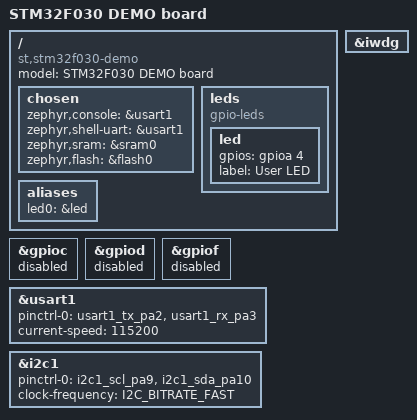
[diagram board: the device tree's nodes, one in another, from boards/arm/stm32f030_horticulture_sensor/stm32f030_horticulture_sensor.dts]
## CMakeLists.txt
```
set(BOARD_ROOT ${CMAKE_CURRENT_LIST_DIR})
set(BOARD stm32f030_horticulture_sensor)
# ===== DO NOT REMOVE =====
cmake_minimum_required(VERSION 3.13.1)
include($ENV{ZEPHYR_BASE}/cmake/app/boilerplate.cmake NO_POLICY_SCOPE)
# ===== DO NOT REMOVE =====

project(stm32-gauge)

target_sources(app PRIVATE src/main.c)


# This sample is only compatible with nrf52840_pca10065 because it has
# re-directed the 'boards' directory to a directory that only contains
# this board.
```

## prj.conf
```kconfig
# nothing here
CONFIG_GPIO=y
CONFIG_I2C_SLAVE=y
```

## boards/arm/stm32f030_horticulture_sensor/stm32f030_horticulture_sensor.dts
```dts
/*
 * Copyright (c) 2019 Antony Pavlov <antonynpavlov@gmail.com>
 *
 * SPDX-License-Identifier: Apache-2.0
 */

/dts-v1/;
#include <st/f0/stm32f030X4.dtsi>
#include <st/f0/stm32f030f4px-pinctrl.dtsi>

/ {
	model = "STM32F030 DEMO board";
	compatible = "st,stm32f030-demo";

	chosen {
		zephyr,console = &usart1;
		zephyr,shell-uart = &usart1;
		zephyr,sram = &sram0;
		zephyr,flash = &flash0;
	};

	leds {
		compatible = "gpio-leds";
		led: led {
			gpios = <&gpioa 4 GPIO_ACTIVE_HIGH>;
			label = "User LED";
		};
	};

	aliases {
		led0 = &led;
	};
};

/* Due to limited available memory, don't enable gpioc,d,e,f */
&gpioc {status = "disabled";};
&gpiod {status = "disabled";};
&gpiof {status = "disabled";};

&usart1 {
	pinctrl-0 = <&usart1_tx_pa2 &usart1_rx_pa3>;
	current-speed = <115200>;
	status = "okay";
};
&i2c1 {
	pinctrl-0 = < &i2c1_scl_pa9 &i2c1_sda_pa10 >;
	status = "okay";
	clock-frequency = <I2C_BITRATE_FAST>;
};


&iwdg {
	status = "okay";
};
```

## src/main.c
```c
/*
 * Copyright (c) 2016 Intel Corporation
 *
 * SPDX-License-Identifier: Apache-2.0
 */

#include <zephyr.h>
#include <device.h>
#include <devicetree.h>
#include <drivers/gpio.h>
#include <drivers/i2c.h>

/* 1000 msec = 1 sec */


/* The devicetree node identifier for the "led0" alias. */

/*
struct i2c_slave_callbacks {
	# callback function being called when write is requested 
	i2c_slave_write_requested_cb_t write_requested;
	# callback function being called when read is requested 
	i2c_slave_read_requested_cb_t read_requested;
	# callback function being called when byte has been received 
	i2c_slave_write_received_cb_t write_received;
	# callback function being called when byte has been sent 
	i2c_slave_read_processed_cb_t read_processed;
	# callback function being called when stop occurs on the bus 
	i2c_slave_stop_cb_t stop;
};
*/
void	i2c_write_requested(){
	printk("I2C: Write requested\n");
}
void	i2c_read_requested(){
	printk("I2C: Read requested\n");
}
void	i2c_write_received(){
	printk("I2C: write_received\n");
}
void	i2c_read_processed(){
	printk("I2C: read_processed\n");
}
void	i2c_read_processed(){
	printk("I2C: stop\n");
}
/*
struct i2c_slave_config {
	# Private, do not modify 
	sys_snode_t node;
	# Flags for the slave device defined by I2C_SLAVE_FLAGS_* constants 
	uint8_t flags;
	# Address for this slave device 
	uint16_t address;
	# Callback functions 
	const struct i2c_slave_callbacks *callbacks;
};
*/

i2c_slave_config i2c_config;


#define I2C_DEV "I2C_0"


void main(void)
{
const struct device *i2c_dev;
	i2c_dev = device_get_binding(I2C_DEV);
	if (!i2c_dev) {
		printk("I2C: Device driver not found.\n");
		return;
	}
	i2c_slave_register(i2c_dev, &i2c_config);

printk("EndOfMain");

}
```
